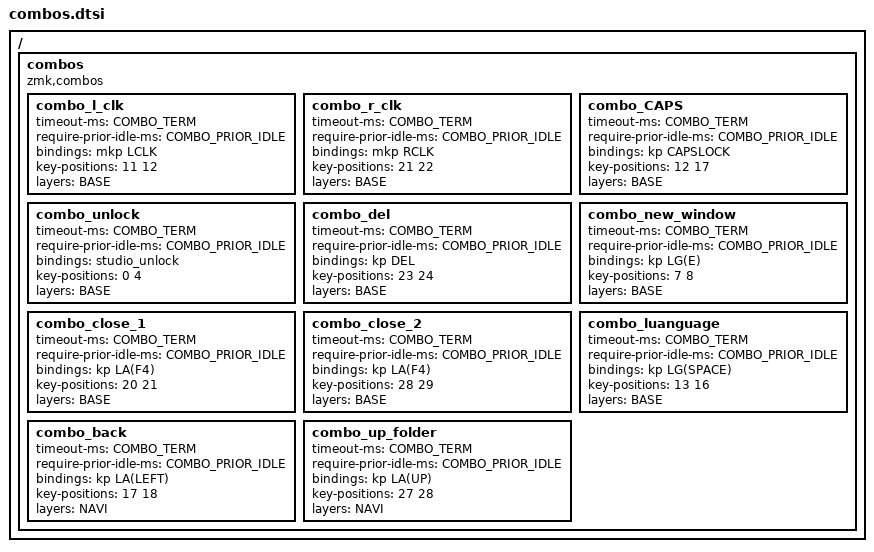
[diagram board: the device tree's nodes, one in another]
#define COMBO_TERM 20        // window (ms) for both combo keys to be pressed
#define COMBO_PRIOR_IDLE 250      // must be idle this long before a combo can trigger (prevents accidental combos while typing)

/ {
    combos {
        compatible = "zmk,combos";

        //INFO: Mouse clicks
        combo_l_clk {
            timeout-ms = <COMBO_TERM>;
            require-prior-idle-ms = <COMBO_PRIOR_IDLE>;
            bindings = <&mkp LCLK>;
            key-positions = <11 12>;
            layers = <BASE>;
        };

        combo_r_clk {
            timeout-ms = <COMBO_TERM>;
            require-prior-idle-ms = <COMBO_PRIOR_IDLE>;
            bindings = <&mkp RCLK>;
            key-positions = <21 22>;
            layers = <BASE>;
        };

        //INFO: System commands
        combo_CAPS {
            timeout-ms = <COMBO_TERM>;
            require-prior-idle-ms = <COMBO_PRIOR_IDLE>;
            bindings = <&kp CAPSLOCK>;
            key-positions = <12 17>;
            layers = <BASE>;
        };

        combo_unlock {
            timeout-ms = <COMBO_TERM>;
            require-prior-idle-ms = <COMBO_PRIOR_IDLE>;
            bindings = <&studio_unlock>;
            key-positions = <0 4>;
            layers = <BASE>;
        };

        combo_del {
            timeout-ms = <COMBO_TERM>;
            require-prior-idle-ms = <COMBO_PRIOR_IDLE>;
            bindings = <&kp DEL>;
            key-positions = <23 24>;
            layers = <BASE>;
        };

        //INFO: Window management
        combo_new_window {
            timeout-ms = <COMBO_TERM>;
            require-prior-idle-ms = <COMBO_PRIOR_IDLE>;
            bindings = <&kp LG(E)>;
            key-positions = <7 8>;
            layers = <BASE>;
        };

        combo_close_1 {
            timeout-ms = <COMBO_TERM>;
            require-prior-idle-ms = <COMBO_PRIOR_IDLE>;
            bindings = <&kp LA(F4)>;
            key-positions = <20 21>;
            layers = <BASE>;
        };

        combo_close_2 {
            timeout-ms = <COMBO_TERM>;
            require-prior-idle-ms = <COMBO_PRIOR_IDLE>;
            bindings = <&kp LA(F4)>;
            key-positions = <28 29>;
            layers = <BASE>;
        };

        combo_luanguage {
            timeout-ms = <COMBO_TERM>;
            require-prior-idle-ms = <COMBO_PRIOR_IDLE>;
            bindings = <&kp LG(SPACE)>;
            key-positions = <13 16>;
            layers = <BASE>;
        };

        //INFO: Navigation (NAVI layer)
        combo_back {
            timeout-ms = <COMBO_TERM>;
            require-prior-idle-ms = <COMBO_PRIOR_IDLE>;
            bindings = <&kp LA(LEFT)>;
            key-positions = <17 18>;
            layers = <NAVI>;
        };

        combo_up_folder {
            timeout-ms = <COMBO_TERM>;
            require-prior-idle-ms = <COMBO_PRIOR_IDLE>;
            bindings = <&kp LA(UP)>;
            key-positions = <27 28>;
            layers = <NAVI>;
        };
    };
};
